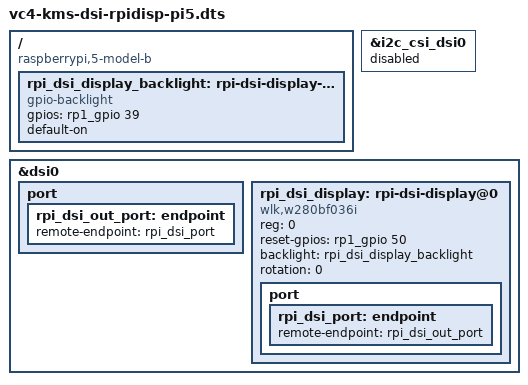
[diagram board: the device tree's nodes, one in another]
/dts-v1/;
/plugin/;
/ {
	compatible = "raspberrypi,5-model-b","brcm,bcm2712";
	
	fragment@0 {
		target-path="/";
		__overlay__ {
			rpi_dsi_display_backlight:rpi-dsi-display-backlight {
				compatible = "gpio-backlight";
				gpios = <&rp1_gpio 39 0>;
				default-on;
			};
		};
	};
	
	fragment@1 {
		target = <&i2c_csi_dsi0>;
		__overlay__ {
			status = "disabled";
		};
	};
	
	fragment@2 {
		target = <&dsi0>;
		__overlay__{
			status = "okay";
			#address-cells = <1>;
			#size-cells = <0>;
			port {
				rpi_dsi_out_port:endpoint {
					remote-endpoint = <&rpi_dsi_port>;
				};
			};
			
			rpi_dsi_display:rpi-dsi-display@0 {
				compatible    = "wlk,w280bf036i";
				status        = "okay";
				reg           = <0>;
				// reset-gpios   = <&gpio 38 0>;
				reset-gpios   = <&rp1_gpio 50 0>;// fix me
				backlight = <&rpi_dsi_display_backlight>;
				rotation = <0>;
				port {
					rpi_dsi_port: endpoint {
						remote-endpoint = <&rpi_dsi_out_port>;
					};
				};
			};
		};
	};
};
